AUTOSAR XML (schema 00050)
package /COM/VECTOR/CFG/WORKFLOW/SYSDESC/SYNC
  system SYSTEM: category=ECU_EXTRACT
    system mapping MAPPINGS
      data-mappings:
        data-element=COMPOSITIONTYPE.PpFault.DeFault, system-signal=Signal_Fan_Fault_f777c54e31a89d5c
        data-element=COMPOSITIONTYPE.PpSpeed.DeSpeed, system-signal=Signal_Fan_Setpoint_7226b1dfc825beac
        data-element=COMPOSITIONTYPE.PpOBDdrivingCycle.DeOBDdrivingCycle, system-signal=Signal_Comfort_DrivingCycle_d5cecd98dc1c368d
    root-software-compositions:
      root sw composition prototype COMPOSITIONTYPE: flat-map=FLATMAP, software-composition=COMPOSITIONTYPE
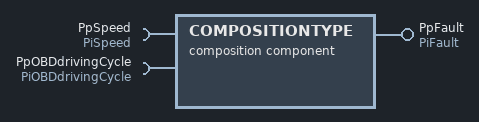
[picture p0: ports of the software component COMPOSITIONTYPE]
  composition sw component type COMPOSITIONTYPE  # UB:Derived from original system description
    provide port PpFault: nonqueued-sender-com-spec{data-element=DeFault, init-value=0}, provided-interface=PiFault
    require port PpSpeed: nonqueued-receiver-com-spec{data-element=DeSpeed, filter=data-filter-type=ALWAYS, init-value=0}, required-interface=PiSpeed
    require port PpOBDdrivingCycle: nonqueued-receiver-com-spec{data-element=DeOBDdrivingCycle, init-value=1}, required-interface=PiOBDdrivingCycle
    10 x component:
      Det: type=Det
      ComM: type=ComM
      EcuM: type=EcuM
      BswM: type=BswM
      CpCddIoHwAb: type=CtCddIoHwAb
      CpApController: type=CtApController
      DemMaster_0: type=DemMaster_0
      DemSatellite_0: type=DemSatellite_0
      NvM: type=NvM
      Dcm: type=Dcm
    connect CpCddIoHwAb.PpPwmDcIoHwAb -> CpApController.PpPwmDcIoHwAb  # UB:Derived from original system description
    connect CpCddIoHwAb.PpPwmDeInitIoHwAb -> CpApController.PpPwmDeInitIoHwAb  # UB:Derived from original system description
    connect CpCddIoHwAb.PpPwmInitIoHwAb -> CpApController.PpPwmInitIoHwAb  # UB:Derived from original system description
    connect CpCddIoHwAb.PpAdcReadIoHwAb -> CpApController.PpAdcReadIoHwAb  # UB:Derived from original system description
    connect CpApController.PpBswMRunRequestCtApController -> BswM.Request_ESH_RunRequest_0
    connect CpApController.PpBswMPostRunRequestCtApController -> BswM.Request_ESH_PostRunRequest_0
    delegate CpApController.PpFault <-> outer port PpFault  # UB:Derived from original system description
    delegate CpApController.PpSpeed <-> outer port PpSpeed  # UB:Derived from original system description
    connect ComM.UR_Connector_Fan_ECU_fbc5880ce1a0cdea_1e36b570 -> CpApController.PpComMUserRequestCtApController
    connect BswM.Switch_ESH_ModeSwitch -> BswM.Notification_ESH_ModeNotification
    connect CpApController.DataServices_Fan_Current_Power_Current -> Dcm.DataServices_Fan_Current_Power_Current
    connect CpApController.CBReadData_DID_0x2_Current -> DemMaster_0.CBReadData_DID_0x2_Current
    connect DemMaster_0.OpCycle_OBD_driving_cycle -> CpApController.OpCycle_OBD_driving_cycle
    connect DemSatellite_0.Event_Electrical_Fault_Fan_Motor_Control_Circuit_Open -> CpApController.Event_Electrical_Fault_Fan_Motor_Control_Circuit_Open
    connect DemSatellite_0.Event_Electrical_Fault_Fan_Motor_Control_Circuit_Short -> CpApController.Event_Electrical_Fault_Fan_Motor_Control_Circuit_Short
    connect DemSatellite_0.Event_Mechanical_Fault_Unexpected_High_Current -> CpApController.Event_Mechanical_Fault_Unexpected_High_Current
    connect DemSatellite_0.Event_Mechanical_Fault_Unexpected_Low_Current -> CpApController.Event_Mechanical_Fault_Unexpected_Low_Current
    delegate CpApController.PpOBDdrivingCycle <-> outer port PpOBDdrivingCycle  # UB:Derived from original system description
  end to end protection set E2EPROTECTIONSET
  port interface mapping set PORTINTERFACEMAPPINGSET
